AUTOSAR XML (schema 4-2-1)
standard types defined: boolean, uint8, uint16, uint32, uint64, sint8, sint16, sint32, sint64, float32, float64
package /ZARXML_DATA_TYPES
  impl type EDomainId: compu {0=EDomainId_VP, 1=EDomainId_Cluster, 2=EDomainId_IVI, 3=EDomainId_Last}, implementation-data-type=uint8
  impl type ESystemState: compu {0=ESystemState_Off, 1=ESystemState_Startup, 2=ESystemState_Up, 3=ESystemState_FullRun, 4=ESystemState_PrepareShutdown, 5=ESystemState_Minimal, 6=ESystemState_Meet, 7=ESystemState_Shutdown, 8=ESystemState_Last}, implementation-data-type=uint8
  impl type EDisplayPower: compu {0=EDisplayPower_Off, 1=EDisplayPower_On, 2=EDisplayPower_Last}, implementation-data-type=uint8
  4 x impl type:
    data_u8_15: category=ARRAY
      element Element: array-size=15, array-size-semantics=FIXED-SIZE, implementation-data-type=uint8
    data_u8_2: category=ARRAY
      element Element: array-size=2, array-size-semantics=FIXED-SIZE, implementation-data-type=uint8
    data_u8_8: category=ARRAY
      element Element: array-size=8, array-size-semantics=FIXED-SIZE, implementation-data-type=uint8
    EGaugeUnit: compu {0=EGaugeUnit_Mph, 1=EGaugeUnit_Kmph, 2=EGaugeUnit_Centigrade, 3=EGaugeUnit_Farenheit, 4=EGaugeUnit_Psi, 5=EGaugeUnit_Pa, 6=EGaugeUnit_Bar, 7=EGaugeUnit_Kmpl, 8=EGaugeUnit_Mpg, 9=EGaugeUnit_Ltr, 10=EGaugeUnit_Gal, 11=EGaugeUnit_Km, 12=EGaugeUnit_Mile, 13=EGaugeUnit_Last}, implementation-data-type=uint8
  8 x impl type:
    SGaugeInfo: category=STRUCTURE
      5 x element, all with category=TYPE_REFERENCE:
        id: implementation-data-type=uint8
        position: implementation-data-type=uint16
        digitalData: implementation-data-type=sint32
        unit: implementation-data-type=EGaugeUnit
        dynData: implementation-data-type=uint16
    SGaugeInfo_2: category=ARRAY
      element Element: array-size=2, array-size-semantics=FIXED-SIZE, implementation-data-type=SGaugeInfo
    SGaugeInfo_u32dyn: category=STRUCTURE
      5 x element, all with category=TYPE_REFERENCE:
        id: implementation-data-type=uint8
        position: implementation-data-type=uint16
        digitalData: implementation-data-type=uint32
        unit: implementation-data-type=EGaugeUnit
        dynData: implementation-data-type=uint32
    SGaugeInfo_u32dyn_3: category=ARRAY
      element Element: array-size=3, array-size-semantics=FIXED-SIZE, implementation-data-type=SGaugeInfo_u32dyn
    SShiftInd: category=STRUCTURE
      6 x element, all with category=TYPE_REFERENCE, implementation-data-type=uint8:
        Shift_Ind_Pos
        Shift_Ind_BlinkReq
        Shift_Ind_Up
        Shift_Ind_Down
        Shift_Ind_DisplayDecState
        Shift_Ind_Screen_ShiftType
    data_u8_64: category=ARRAY
      element Element: array-size=64, array-size-semantics=FIXED-SIZE, implementation-data-type=uint8
    data_u8_512: category=ARRAY
      element Element: array-size=512, array-size-semantics=FIXED-SIZE, implementation-data-type=uint8
    EDidType: compu {0=EDidType_Read, 1=EDidType_Write, 2=EDidType_Last}, implementation-data-type=uint8
  impl type data_u8_256: category=ARRAY
    element Element: array-size=256, array-size-semantics=FIXED-SIZE, implementation-data-type=uint8
  impl type EIOCtrlOptType: compu {0=EIOCtrlOptType_returnControlToECU, 1=EIOCtrlOptType_resetToDefault, 2=EIOCtrlOptType_freezeCurrentState, 3=EIOCtrlOptType_shortTermAdjustment, 4=EIOCtrlOptType_Last}, implementation-data-type=uint8
  impl type ERoutineType: compu {0=ERoutineType_Start, 1=ERoutineType_Stop, 2=ERoutineType_QueryResults, 3=ERoutineType_Last}, implementation-data-type=uint8
  impl type ECompState: compu {0=ECompState_Init, 1=ECompState_Start, 2=ECompState_Run, 3=ECompState_Stop, 4=ECompState_Shutdown, 5=ECompState_Last}, implementation-data-type=uint8
  impl type data_u8_32: category=ARRAY
    element Element: array-size=32, array-size-semantics=FIXED-SIZE, implementation-data-type=uint8
  impl type EDisplayStatus: compu {0=EDisplayState_Off, 1=EDisplayState_On, 2=EDisplayState_Error, 3=EDisplayState_Disconnected, 4=EDisplayState_Last}, implementation-data-type=uint8
  47 x impl type:
    data_u8_10: category=ARRAY
      element Element: array-size=10, array-size-semantics=FIXED-SIZE, implementation-data-type=uint8
    SPowerSystemStateReqChange: category=STRUCTURE
      element domainId: implementation-data-type=EDomainId
      element state: implementation-data-type=ESystemState
    SHealthDumpGetHdr: category=STRUCTURE
      element encrypt: implementation-data-type=uint8
    SHealthDumpGetData: category=STRUCTURE
      element reserved: implementation-data-type=uint8
    SDisplaySetPower: category=STRUCTURE
      element displayId: implementation-data-type=uint32
      element state: implementation-data-type=EDisplayPower
    STT_Status: category=STRUCTURE
      element mask: implementation-data-type=data_u8_15
    SRTT_Toggle: category=STRUCTURE
      element positions: implementation-data-type=uint8
      element display: implementation-data-type=uint8
    SFRTT_Status: category=STRUCTURE
      element mask: implementation-data-type=data_u8_2
    SRTT_Icon: category=STRUCTURE
      element icon: implementation-data-type=data_u8_2
    SRTT_Status: category=STRUCTURE
      element mask: implementation-data-type=data_u8_2
    SWarningExtDisplay: category=STRUCTURE
      element show: implementation-data-type=uint8
      element warningId: implementation-data-type=uint16
      element dynData: implementation-data-type=data_u8_8
    SWarningDisplay: category=STRUCTURE
      element show: implementation-data-type=uint8
      element warningId: implementation-data-type=uint16
      element dynData: implementation-data-type=data_u8_8
    SSlowGaugeInfo: category=STRUCTURE
      element gaugeInfo: implementation-data-type=SGaugeInfo_2
    SFastGaugeInfo: category=STRUCTURE
      element gaugeInfo: implementation-data-type=SGaugeInfo_u32dyn_3
    SShiftPosIndStatus: category=STRUCTURE
      element status: implementation-data-type=SShiftInd
    SIlluminationData: category=STRUCTURE
      4 x element, all with category=TYPE_REFERENCE, implementation-data-type=uint8:
        data
        dayStep
        nightStep
        daynightStatus
    SUpdateShortServiceReq: category=STRUCTURE
      7 x element, all with category=TYPE_REFERENCE:
        msgId: implementation-data-type=uint16
        msgSize: implementation-data-type=uint16
        memoryType: implementation-data-type=uint8
        memoryCmd: implementation-data-type=uint8
        sid: implementation-data-type=uint8
        length: implementation-data-type=uint32
        data: implementation-data-type=data_u8_64
    SUpdateLongServiceReq: category=STRUCTURE
      7 x element, all with category=TYPE_REFERENCE:
        msgId: implementation-data-type=uint16
        msgSize: implementation-data-type=uint16
        memoryType: implementation-data-type=uint8
        memoryCmd: implementation-data-type=uint8
        sid: implementation-data-type=uint8
        length: implementation-data-type=uint32
        data: implementation-data-type=data_u8_512
    SDiagDIDRequest: category=STRUCTURE
      4 x element, all with category=TYPE_REFERENCE:
        did: implementation-data-type=uint16
        didType: implementation-data-type=EDidType
        dataLen: implementation-data-type=uint16
        data: implementation-data-type=data_u8_256
    SDiagIOCtrlRequest: category=STRUCTURE
      4 x element, all with category=TYPE_REFERENCE:
        did: implementation-data-type=uint16
        optionCtrl: implementation-data-type=EIOCtrlOptType
        dataLen: implementation-data-type=uint16
        data: implementation-data-type=data_u8_256
    SDiagRoutineRequest: category=STRUCTURE
      4 x element, all with category=TYPE_REFERENCE:
        routineId: implementation-data-type=uint16
        routineType: implementation-data-type=ERoutineType
        dataLen: implementation-data-type=uint16
        data: implementation-data-type=data_u8_256
    SDLTMessageReadRequest: category=STRUCTURE
      element status: implementation-data-type=data_u8_2
    SDLTControlMessageReponse: category=STRUCTURE
      element status: implementation-data-type=data_u8_2
    SPowerSystemState: category=STRUCTURE
      element domainId: implementation-data-type=EDomainId
      element state: implementation-data-type=ESystemState
    SPowerExtendShutdownTime: category=STRUCTURE
      element domainId: implementation-data-type=EDomainId
      element timeoutMs: implementation-data-type=uint32
    SPowerKeepSystemAwake: category=STRUCTURE
      element domainId: implementation-data-type=EDomainId
      element timeoutMs: implementation-data-type=uint32
    SPowerSystemStateReqWakeLock: category=STRUCTURE
      element enable: implementation-data-type=uint8
      element requiredTimeMs: implementation-data-type=uint32
    SPowerReportCompState: category=STRUCTURE
      element state: implementation-data-type=ECompState
    SUclErrorNotify: category=STRUCTURE
      element errorCode: implementation-data-type=sint32
    SUclLinkStatus: category=STRUCTURE
      element status: implementation-data-type=sint32
    SHealthDomainHeartbeat: category=STRUCTURE
      element domainId: implementation-data-type=EDomainId
      element seqCnt: implementation-data-type=uint32
    SHealthDomainFatalError: category=STRUCTURE
      element domainId: implementation-data-type=EDomainId
      element compIdx: implementation-data-type=uint32
    SHealthEventRecord: category=STRUCTURE
      element recordType: implementation-data-type=uint8
      element recordLen: implementation-data-type=uint8
      element recordData: implementation-data-type=data_u8_8
    SHealthDumpHdrInfo: category=STRUCTURE
      element fileSize: implementation-data-type=uint32
    SHealthDumpData: category=STRUCTURE
      element chunkSize: implementation-data-type=uint32
      element data: implementation-data-type=data_u8_32
    SHealthGetStatus: category=STRUCTURE
      element compIdx: implementation-data-type=uint8
    SHealthStatusReport: category=STRUCTURE
      element timestamp: implementation-data-type=uint32
      element dataLen: implementation-data-type=uint16
      element data: implementation-data-type=data_u8_256
    SDisplayCurrentState: category=STRUCTURE
      element displayId: implementation-data-type=uint32
      element state: implementation-data-type=EDisplayStatus
    SEmmcErrorNotifier: category=STRUCTURE
      element errorCode: implementation-data-type=uint32
    SWarningDisplayAvailable: category=STRUCTURE
      element status: implementation-data-type=uint8
    SWarningStatus: category=STRUCTURE
      element visible: implementation-data-type=uint8
      element warningId: implementation-data-type=uint16
      element dynData: implementation-data-type=data_u8_10
    SSafeHMIReadyStatus: category=STRUCTURE
      element status: implementation-data-type=uint8
    SMainHMIReadyStatus: category=STRUCTURE
      element status: implementation-data-type=uint8
    SUpdateShortServiceResp: category=STRUCTURE
      7 x element, all with category=TYPE_REFERENCE:
        msgId: implementation-data-type=uint16
        msgSize: implementation-data-type=uint16
        sid: implementation-data-type=uint8
        length: implementation-data-type=uint16
        responseCode: implementation-data-type=uint8
        NRC: implementation-data-type=uint8
        data: implementation-data-type=data_u8_64
    SDiagResponse: category=STRUCTURE
      element responseCode: implementation-data-type=uint8
      element dataLen: implementation-data-type=uint16
      element data: implementation-data-type=data_u8_256
    SDLTMessageReadAck: category=STRUCTURE
      element status: implementation-data-type=data_u8_2
    SDLTControlMessageRequest: category=STRUCTURE
      element status: implementation-data-type=data_u8_2
package /ZARXML_PORT_IF
  46 x sender receiver interface:
    PowerSystemStateReqChange: invalidation-policy=PowerSystemStateReqChangeData
      data PowerSystemStateReqChangeData: type=SPowerSystemStateReqChange
    HealthDumpGetHdr_Q: invalidation-policy=HealthDumpGetHdrData
      data HealthDumpGetHdrData: sw-impl-policy=QUEUED, type=SHealthDumpGetHdr
    HealthDumpGetData_Q: invalidation-policy=HealthDumpGetDataData
      data HealthDumpGetDataData: sw-impl-policy=QUEUED, type=SHealthDumpGetData
    DisplaySetPower: invalidation-policy=DisplaySetPowerData
      data DisplaySetPowerData: type=SDisplaySetPower
    TT_Status: invalidation-policy=TT_StatusData
      data TT_StatusData: type=STT_Status
    RTT_Toggle: invalidation-policy=RTT_ToggleData
      data RTT_ToggleData: type=SRTT_Toggle
    FRTT_Status: invalidation-policy=FRTT_StatusData
      data FRTT_StatusData: type=SFRTT_Status
    RTT_Icon: invalidation-policy=RTT_IconData
      data RTT_IconData: type=SRTT_Icon
    RTT_Status: invalidation-policy=RTT_StatusData
      data RTT_StatusData: type=SRTT_Status
    WarningExtDisplay: invalidation-policy=WarningExtDisplayData
      data WarningExtDisplayData: type=SWarningExtDisplay
    WarningDisplay: invalidation-policy=WarningDisplayData
      data WarningDisplayData: type=SWarningDisplay
    SlowGaugeInfo: invalidation-policy=SlowGaugeInfoData
      data SlowGaugeInfoData: type=SSlowGaugeInfo
    FastGaugeInfo: invalidation-policy=FastGaugeInfoData
      data FastGaugeInfoData: type=SFastGaugeInfo
    ShiftPosIndStatus: invalidation-policy=ShiftPosIndStatusData
      data ShiftPosIndStatusData: type=SShiftPosIndStatus
    IlluminationData: invalidation-policy=IlluminationDataData
      data IlluminationDataData: type=SIlluminationData
    UpdateShortServiceReq_Q: invalidation-policy=UpdateShortServiceReqData
      data UpdateShortServiceReqData: sw-impl-policy=QUEUED, type=SUpdateShortServiceReq
    UpdateLongServiceReq_Q: invalidation-policy=UpdateLongServiceReqData
      data UpdateLongServiceReqData: sw-impl-policy=QUEUED, type=SUpdateLongServiceReq
    DiagDIDRequest_Q: invalidation-policy=DiagDIDRequestData
      data DiagDIDRequestData: sw-impl-policy=QUEUED, type=SDiagDIDRequest
    DiagIOCtrlRequest_Q: invalidation-policy=DiagIOCtrlRequestData
      data DiagIOCtrlRequestData: sw-impl-policy=QUEUED, type=SDiagIOCtrlRequest
    DiagRoutineRequest_Q: invalidation-policy=DiagRoutineRequestData
      data DiagRoutineRequestData: sw-impl-policy=QUEUED, type=SDiagRoutineRequest
    DLTMessageReadRequest: invalidation-policy=DLTMessageReadRequestData
      data DLTMessageReadRequestData: type=SDLTMessageReadRequest
    DLTControlMessageReponse: invalidation-policy=DLTControlMessageReponseData
      data DLTControlMessageReponseData: type=SDLTControlMessageReponse
    PowerSystemState: invalidation-policy=PowerSystemStateData
      data PowerSystemStateData: type=SPowerSystemState
    PowerExtendShutdownTime_Q: invalidation-policy=PowerExtendShutdownTimeData
      data PowerExtendShutdownTimeData: sw-impl-policy=QUEUED, type=SPowerExtendShutdownTime
    PowerKeepSystemAwake_Q: invalidation-policy=PowerKeepSystemAwakeData
      data PowerKeepSystemAwakeData: sw-impl-policy=QUEUED, type=SPowerKeepSystemAwake
    PowerSystemStateReqWakeLock_Q: invalidation-policy=PowerSystemStateReqWakeLockData
      data PowerSystemStateReqWakeLockData: sw-impl-policy=QUEUED, type=SPowerSystemStateReqWakeLock
    PowerReportCompState_Q: invalidation-policy=PowerReportCompStateData
      data PowerReportCompStateData: sw-impl-policy=QUEUED, type=SPowerReportCompState
    UclErrorNotify_Q: invalidation-policy=UclErrorNotifyData
      data UclErrorNotifyData: sw-impl-policy=QUEUED, type=SUclErrorNotify
    UclLinkStatus_Q: invalidation-policy=UclLinkStatusData
      data UclLinkStatusData: sw-impl-policy=QUEUED, type=SUclLinkStatus
    HealthDomainHeartbeat_Q: invalidation-policy=HealthDomainHeartbeatData
      data HealthDomainHeartbeatData: sw-impl-policy=QUEUED, type=SHealthDomainHeartbeat
    HealthDomainFatalError_Q: invalidation-policy=HealthDomainFatalErrorData
      data HealthDomainFatalErrorData: sw-impl-policy=QUEUED, type=SHealthDomainFatalError
    HealthEventRecord_Q: invalidation-policy=HealthEventRecordData
      data HealthEventRecordData: sw-impl-policy=QUEUED, type=SHealthEventRecord
    HealthDumpHdrInfo_Q: invalidation-policy=HealthDumpHdrInfoData
      data HealthDumpHdrInfoData: sw-impl-policy=QUEUED, type=SHealthDumpHdrInfo
    HealthDumpData_Q: invalidation-policy=HealthDumpDataData
      data HealthDumpDataData: sw-impl-policy=QUEUED, type=SHealthDumpData
    HealthGetStatus_Q: invalidation-policy=HealthGetStatusData
      data HealthGetStatusData: sw-impl-policy=QUEUED, type=SHealthGetStatus
    HealthStatusReport_Q: invalidation-policy=HealthStatusReportData
      data HealthStatusReportData: sw-impl-policy=QUEUED, type=SHealthStatusReport
    DisplayCurrentState: invalidation-policy=DisplayCurrentStateData
      data DisplayCurrentStateData: type=SDisplayCurrentState
    EmmcErrorNotifier: invalidation-policy=EmmcErrorNotifierData
      data EmmcErrorNotifierData: type=SEmmcErrorNotifier
    WarningDisplayAvailable: invalidation-policy=WarningDisplayAvailableData
      data WarningDisplayAvailableData: type=SWarningDisplayAvailable
    WarningStatus: invalidation-policy=WarningStatusData
      data WarningStatusData: type=SWarningStatus
    SafeHMIReadyStatus_Q: invalidation-policy=SafeHMIReadyStatusData
      data SafeHMIReadyStatusData: sw-impl-policy=QUEUED, type=SSafeHMIReadyStatus
    MainHMIReadyStatus_Q: invalidation-policy=MainHMIReadyStatusData
      data MainHMIReadyStatusData: sw-impl-policy=QUEUED, type=SMainHMIReadyStatus
    UpdateShortServiceResp_Q: invalidation-policy=UpdateShortServiceRespData
      data UpdateShortServiceRespData: sw-impl-policy=QUEUED, type=SUpdateShortServiceResp
    DiagResponse_Q: invalidation-policy=DiagResponseData
      data DiagResponseData: sw-impl-policy=QUEUED, type=SDiagResponse
    DLTMessageReadAck: invalidation-policy=DLTMessageReadAckData
      data DLTMessageReadAckData: type=SDLTMessageReadAck
    DLTControlMessageRequest: invalidation-policy=DLTControlMessageRequestData
      data DLTControlMessageRequestData: type=SDLTControlMessageRequest
  client server interface UclInitShutdown
    operation Initialize: possible-error=UclInitShutdown/E_OK
    operation Shutdown: possible-error=UclInitShutdown/E_OK
    error E_OK: error-code=0
  client server interface UclCmplibCmd
    operation OnCommand: possible-error=UclCmplibCmd/E_OK
      arg Cmd: type=uint8, direction=IN
    error E_OK: error-code=0
  client server interface UclSystemCallbacks
    operation ErrorNotification
      arg DLInst: type=uint8, direction=IN
      arg ErrorCode: type=sint32, direction=IN
    operation LinkStatusChanged
      arg DLInst: type=uint8, direction=IN
      arg Status: type=sint32, direction=IN
  sender receiver interface UclTxStatuses
package /ZARXML_CMP
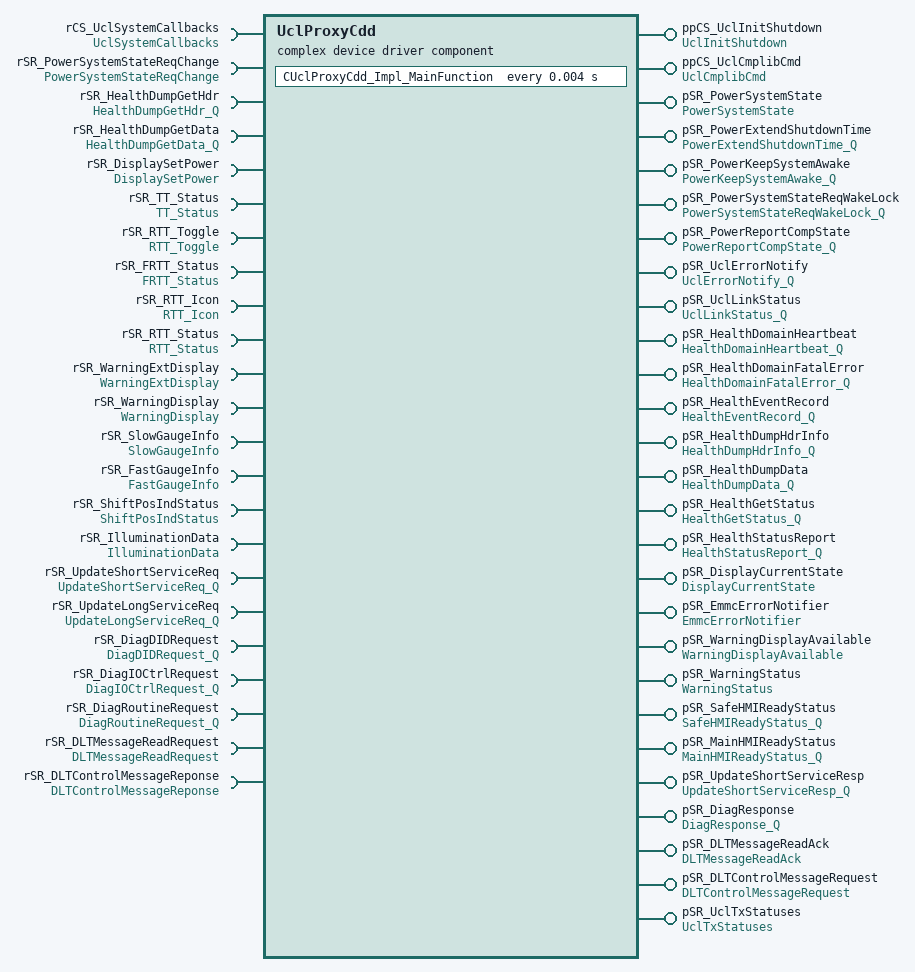
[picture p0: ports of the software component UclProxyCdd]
  complex device driver sw component type UclProxyCdd
    provide port ppCS_UclInitShutdown: provided-interface=UclInitShutdown
    provide port ppCS_UclCmplibCmd: provided-interface=UclCmplibCmd
    require port rCS_UclSystemCallbacks: required-interface=UclSystemCallbacks
    24 x provide port:
      pSR_PowerSystemState: nonqueued-sender-com-spec{data-element=PowerSystemStateData, init-value={short-label=SPowerSystemState, fields=[EDomainId:0, ESystemState:0]}}, provided-interface=PowerSystemState
      pSR_PowerExtendShutdownTime: queued-sender-com-spec=data-element=PowerExtendShutdownTimeData, provided-interface=PowerExtendShutdownTime_Q
      pSR_PowerKeepSystemAwake: queued-sender-com-spec=data-element=PowerKeepSystemAwakeData, provided-interface=PowerKeepSystemAwake_Q
      pSR_PowerSystemStateReqWakeLock: queued-sender-com-spec=data-element=PowerSystemStateReqWakeLockData, provided-interface=PowerSystemStateReqWakeLock_Q
      pSR_PowerReportCompState: queued-sender-com-spec=data-element=PowerReportCompStateData, provided-interface=PowerReportCompState_Q
      pSR_UclErrorNotify: queued-sender-com-spec=data-element=UclErrorNotifyData, provided-interface=UclErrorNotify_Q
      pSR_UclLinkStatus: queued-sender-com-spec=data-element=UclLinkStatusData, provided-interface=UclLinkStatus_Q
      pSR_HealthDomainHeartbeat: queued-sender-com-spec=data-element=HealthDomainHeartbeatData, provided-interface=HealthDomainHeartbeat_Q
      pSR_HealthDomainFatalError: queued-sender-com-spec=data-element=HealthDomainFatalErrorData, provided-interface=HealthDomainFatalError_Q
      pSR_HealthEventRecord: queued-sender-com-spec=data-element=HealthEventRecordData, provided-interface=HealthEventRecord_Q
      pSR_HealthDumpHdrInfo: queued-sender-com-spec=data-element=HealthDumpHdrInfoData, provided-interface=HealthDumpHdrInfo_Q
      pSR_HealthDumpData: queued-sender-com-spec=data-element=HealthDumpDataData, provided-interface=HealthDumpData_Q
      pSR_HealthGetStatus: queued-sender-com-spec=data-element=HealthGetStatusData, provided-interface=HealthGetStatus_Q
      pSR_HealthStatusReport: queued-sender-com-spec=data-element=HealthStatusReportData, provided-interface=HealthStatusReport_Q
      pSR_DisplayCurrentState: nonqueued-sender-com-spec{data-element=DisplayCurrentStateData, init-value={short-label=SDisplayCurrentState, fields=[uint32:0, EDisplayStatus:0]}}, provided-interface=DisplayCurrentState
      pSR_EmmcErrorNotifier: nonqueued-sender-com-spec{data-element=EmmcErrorNotifierData, init-value={short-label=SEmmcErrorNotifier, fields=uint32:0}}, provided-interface=EmmcErrorNotifier
      pSR_WarningDisplayAvailable: nonqueued-sender-com-spec{data-element=WarningDisplayAvailableData, init-value={short-label=SWarningDisplayAvailable, fields=uint8:0}}, provided-interface=WarningDisplayAvailable
      pSR_WarningStatus: nonqueued-sender-com-spec{data-element=WarningStatusData, init-value={short-label=SWarningStatus, fields=[uint8:0, uint16:0, data_u8_10:10 x uint8:0]}}, provided-interface=WarningStatus
      pSR_SafeHMIReadyStatus: queued-sender-com-spec=data-element=SafeHMIReadyStatusData, provided-interface=SafeHMIReadyStatus_Q
      pSR_MainHMIReadyStatus: queued-sender-com-spec=data-element=MainHMIReadyStatusData, provided-interface=MainHMIReadyStatus_Q
      pSR_UpdateShortServiceResp: queued-sender-com-spec=data-element=UpdateShortServiceRespData, provided-interface=UpdateShortServiceResp_Q
      pSR_DiagResponse: queued-sender-com-spec=data-element=DiagResponseData, provided-interface=DiagResponse_Q
      pSR_DLTMessageReadAck: nonqueued-sender-com-spec{data-element=DLTMessageReadAckData, init-value={short-label=SDLTMessageReadAck, fields=data_u8_2:[uint8:0, uint8:0]}}, provided-interface=DLTMessageReadAck
      pSR_DLTControlMessageRequest: nonqueued-sender-com-spec{data-element=DLTControlMessageRequestData, init-value={short-label=SDLTControlMessageRequest, fields=data_u8_2:[uint8:0, uint8:0]}}, provided-interface=DLTControlMessageRequest
    22 x require port:
      rSR_PowerSystemStateReqChange: nonqueued-receiver-com-spec{data-element=PowerSystemStateReqChangeData, init-value={short-label=SPowerSystemStateReqChange, fields=[EDomainId:0, ESystemState:ESystemState_Last]}}, required-interface=PowerSystemStateReqChange
      rSR_HealthDumpGetHdr: queued-receiver-com-spec{data-element=HealthDumpGetHdrData, queue-length=1}, required-interface=HealthDumpGetHdr_Q
      rSR_HealthDumpGetData: queued-receiver-com-spec{data-element=HealthDumpGetDataData, queue-length=1}, required-interface=HealthDumpGetData_Q
      rSR_DisplaySetPower: nonqueued-receiver-com-spec{data-element=DisplaySetPowerData, init-value={short-label=SDisplaySetPower, fields=[uint32:0, EDisplayPower:0]}}, required-interface=DisplaySetPower
      rSR_TT_Status: nonqueued-receiver-com-spec{data-element=TT_StatusData, init-value={short-label=STT_Status, fields=data_u8_15:15 x uint8:0}}, required-interface=TT_Status
      rSR_RTT_Toggle: nonqueued-receiver-com-spec{data-element=RTT_ToggleData, init-value={short-label=SRTT_Toggle, fields=[uint8:0, uint8:0]}}, required-interface=RTT_Toggle
      rSR_FRTT_Status: nonqueued-receiver-com-spec{data-element=FRTT_StatusData, init-value={short-label=SFRTT_Status, fields=data_u8_2:[uint8:0, uint8:0]}}, required-interface=FRTT_Status
      rSR_RTT_Icon: nonqueued-receiver-com-spec{data-element=RTT_IconData, init-value={short-label=SRTT_Icon, fields=data_u8_2:[uint8:0, uint8:0]}}, required-interface=RTT_Icon
      rSR_RTT_Status: nonqueued-receiver-com-spec{data-element=RTT_StatusData, init-value={short-label=SRTT_Status, fields=data_u8_2:[uint8:0, uint8:0]}}, required-interface=RTT_Status
      rSR_WarningExtDisplay: nonqueued-receiver-com-spec{data-element=WarningExtDisplayData, init-value={short-label=SWarningExtDisplay, fields=[uint8:0, uint16:0, data_u8_8:8 x uint8:0]}}, required-interface=WarningExtDisplay
      rSR_WarningDisplay: nonqueued-receiver-com-spec{data-element=WarningDisplayData, init-value={short-label=SWarningDisplay, fields=[uint8:0, uint16:0, data_u8_8:8 x uint8:0]}}, required-interface=WarningDisplay
      rSR_SlowGaugeInfo: nonqueued-receiver-com-spec{data-element=SlowGaugeInfoData, init-value={short-label=SSlowGaugeInfo, fields=SGaugeInfo_2:[{short-label=SGaugeInfo, fields=[uint8:0, uint16:0, sint32:0, EGaugeUnit:EGaugeUnit_Last, uint16:0]}, {short-label=SGaugeInfo, fields=[uint8:0, uint16:0, sint32:0, EGaugeUnit:EGaugeUnit_Last, uint16:0]}]}}, required-interface=SlowGaugeInfo
      rSR_FastGaugeInfo: nonqueued-receiver-com-spec{data-element=FastGaugeInfoData, init-value={short-label=SFastGaugeInfo, fields=SGaugeInfo_u32dyn_3:[{short-label=SGaugeInfo_u32dyn, fields=[uint8:0, uint16:0, uint32:0, EGaugeUnit:EGaugeUnit_Last, uint32:0]}, {short-label=SGaugeInfo_u32dyn, fields=[uint8:0, uint16:0, uint32:0, EGaugeUnit:EGaugeUnit_Last, uint32:0]}, {short-label=SGaugeInfo_u32dyn, fields=[uint8:0, uint16:0, uint32:0, EGaugeUnit:EGaugeUnit_Last, uint32:0]}]}}, required-interface=FastGaugeInfo
      rSR_ShiftPosIndStatus: nonqueued-receiver-com-spec{data-element=ShiftPosIndStatusData, init-value={short-label=SShiftPosIndStatus, fields={short-label=SShiftInd, fields=[uint8:0, uint8:0, uint8:0, uint8:0, uint8:0, uint8:0]}}}, required-interface=ShiftPosIndStatus
      rSR_IlluminationData: nonqueued-receiver-com-spec{data-element=IlluminationDataData, init-value={short-label=SIlluminationData, fields=[uint8:0, uint8:0, uint8:0, uint8:0]}}, required-interface=IlluminationData
      rSR_UpdateShortServiceReq: queued-receiver-com-spec{data-element=UpdateShortServiceReqData, queue-length=2}, required-interface=UpdateShortServiceReq_Q
      rSR_UpdateLongServiceReq: queued-receiver-com-spec{data-element=UpdateLongServiceReqData, queue-length=2}, required-interface=UpdateLongServiceReq_Q
      rSR_DiagDIDRequest: queued-receiver-com-spec{data-element=DiagDIDRequestData, queue-length=2}, required-interface=DiagDIDRequest_Q
      rSR_DiagIOCtrlRequest: queued-receiver-com-spec{data-element=DiagIOCtrlRequestData, queue-length=2}, required-interface=DiagIOCtrlRequest_Q
      rSR_DiagRoutineRequest: queued-receiver-com-spec{data-element=DiagRoutineRequestData, queue-length=2}, required-interface=DiagRoutineRequest_Q
      rSR_DLTMessageReadRequest: nonqueued-receiver-com-spec{data-element=DLTMessageReadRequestData, init-value={short-label=SDLTMessageReadRequest, fields=data_u8_2:[uint8:0, uint8:0]}}, required-interface=DLTMessageReadRequest
      rSR_DLTControlMessageReponse: nonqueued-receiver-com-spec{data-element=DLTControlMessageReponseData, init-value={short-label=SDLTControlMessageReponse, fields=data_u8_2:[uint8:0, uint8:0]}}, required-interface=DLTControlMessageReponse
    provide port pSR_UclTxStatuses: provided-interface=UclTxStatuses
    behavior UclProxyCdd_IB: handle-termination-and-restart=NO-SUPPORT
      operation invoked event OI_ppCS_UclInitShutdown_Initialize: start-on-event=CUclProxyCdd_Impl_Initialize, operation=ppCS_UclInitShutdown.Initialize
      operation invoked event OI_ppCS_UclInitShutdown_Shutdown: start-on-event=CUclProxyCdd_Impl_Shutdown, operation=ppCS_UclInitShutdown.Shutdown
      operation invoked event OI_ppCS_UclCmplibCmd_OnCommand: start-on-event=CUclProxyCdd_Impl_OnCommand, operation=ppCS_UclCmplibCmd.OnCommand
      22 x data received event:
        DRE_rSR_PowerSystemStateReqChange_PowerSystemStateReqChangeData_OnDre_PowerSystemStateReqChange: start-on-event=OnDre_PowerSystemStateReqChange, data=rSR_PowerSystemStateReqChange.PowerSystemStateReqChangeData
        DRE_rSR_HealthDumpGetHdr_HealthDumpGetHdrData_OnDre_HealthDumpGetHdr: start-on-event=OnDre_HealthDumpGetHdr, data=rSR_HealthDumpGetHdr.HealthDumpGetHdrData
        DRE_rSR_HealthDumpGetData_HealthDumpGetDataData_OnDre_HealthDumpGetData: start-on-event=OnDre_HealthDumpGetData, data=rSR_HealthDumpGetData.HealthDumpGetDataData
        DRE_rSR_DisplaySetPower_DisplaySetPowerData_OnDre_DisplaySetPower: start-on-event=OnDre_DisplaySetPower, data=rSR_DisplaySetPower.DisplaySetPowerData
        DRE_rSR_TT_Status_TT_StatusData_OnDre_TT_Status: start-on-event=OnDre_TT_Status, data=rSR_TT_Status.TT_StatusData
        DRE_rSR_RTT_Toggle_RTT_ToggleData_OnDre_RTT_Toggle: start-on-event=OnDre_RTT_Toggle, data=rSR_RTT_Toggle.RTT_ToggleData
        DRE_rSR_FRTT_Status_FRTT_StatusData_OnDre_FRTT_Status: start-on-event=OnDre_FRTT_Status, data=rSR_FRTT_Status.FRTT_StatusData
        DRE_rSR_RTT_Icon_RTT_IconData_OnDre_RTT_Icon: start-on-event=OnDre_RTT_Icon, data=rSR_RTT_Icon.RTT_IconData
        DRE_rSR_RTT_Status_RTT_StatusData_OnDre_RTT_Status: start-on-event=OnDre_RTT_Status, data=rSR_RTT_Status.RTT_StatusData
        DRE_rSR_WarningExtDisplay_WarningExtDisplayData_OnDre_WarningExtDisplay: start-on-event=OnDre_WarningExtDisplay, data=rSR_WarningExtDisplay.WarningExtDisplayData
        DRE_rSR_WarningDisplay_WarningDisplayData_OnDre_WarningDisplay: start-on-event=OnDre_WarningDisplay, data=rSR_WarningDisplay.WarningDisplayData
        DRE_rSR_SlowGaugeInfo_SlowGaugeInfoData_OnDre_SlowGaugeInfo: start-on-event=OnDre_SlowGaugeInfo, data=rSR_SlowGaugeInfo.SlowGaugeInfoData
        DRE_rSR_FastGaugeInfo_FastGaugeInfoData_OnDre_FastGaugeInfo: start-on-event=OnDre_FastGaugeInfo, data=rSR_FastGaugeInfo.FastGaugeInfoData
        DRE_rSR_ShiftPosIndStatus_ShiftPosIndStatusData_OnDre_ShiftPosIndStatus: start-on-event=OnDre_ShiftPosIndStatus, data=rSR_ShiftPosIndStatus.ShiftPosIndStatusData
        DRE_rSR_IlluminationData_IlluminationDataData_OnDre_IlluminationData: start-on-event=OnDre_IlluminationData, data=rSR_IlluminationData.IlluminationDataData
        DRE_rSR_UpdateShortServiceReq_UpdateShortServiceReqData_OnDre_UpdateShortServiceReq: start-on-event=OnDre_UpdateShortServiceReq, data=rSR_UpdateShortServiceReq.UpdateShortServiceReqData
        DRE_rSR_UpdateLongServiceReq_UpdateLongServiceReqData_OnDre_UpdateLongServiceReq: start-on-event=OnDre_UpdateLongServiceReq, data=rSR_UpdateLongServiceReq.UpdateLongServiceReqData
        DRE_rSR_DiagDIDRequest_DiagDIDRequestData_OnDre_DiagDIDRequest: start-on-event=OnDre_DiagDIDRequest, data=rSR_DiagDIDRequest.DiagDIDRequestData
        DRE_rSR_DiagIOCtrlRequest_DiagIOCtrlRequestData_OnDre_DiagIOCtrlRequest: start-on-event=OnDre_DiagIOCtrlRequest, data=rSR_DiagIOCtrlRequest.DiagIOCtrlRequestData
        DRE_rSR_DiagRoutineRequest_DiagRoutineRequestData_OnDre_DiagRoutineRequest: start-on-event=OnDre_DiagRoutineRequest, data=rSR_DiagRoutineRequest.DiagRoutineRequestData
        DRE_rSR_DLTMessageReadRequest_DLTMessageReadRequestData_OnDre_DLTMessageReadRequest: start-on-event=OnDre_DLTMessageReadRequest, data=rSR_DLTMessageReadRequest.DLTMessageReadRequestData
        DRE_rSR_DLTControlMessageReponse_DLTControlMessageReponseData_OnDre_DLTControlMessageReponse: start-on-event=OnDre_DLTControlMessageReponse, data=rSR_DLTControlMessageReponse.DLTControlMessageReponseData
      timing event TE_CUclProxyCdd_Impl_MainFunction: start-on-event=CUclProxyCdd_Impl_MainFunction, period=0.004
      26 x runnable:
        CUclProxyCdd_Impl_MainFunction
          data-receive-point-by-arguments:
            22 x access:
              READ_rSR_PowerSystemStateReqChange_PowerSystemStateReqChangeData: accessed-variable=rSR_PowerSystemStateReqChange.PowerSystemStateReqChangeData
              READ_rSR_HealthDumpGetHdr_HealthDumpGetHdrData: accessed-variable=rSR_HealthDumpGetHdr.HealthDumpGetHdrData
              READ_rSR_HealthDumpGetData_HealthDumpGetDataData: accessed-variable=rSR_HealthDumpGetData.HealthDumpGetDataData
              READ_rSR_DisplaySetPower_DisplaySetPowerData: accessed-variable=rSR_DisplaySetPower.DisplaySetPowerData
              READ_rSR_TT_Status_TT_StatusData: accessed-variable=rSR_TT_Status.TT_StatusData
              READ_rSR_RTT_Toggle_RTT_ToggleData: accessed-variable=rSR_RTT_Toggle.RTT_ToggleData
              READ_rSR_FRTT_Status_FRTT_StatusData: accessed-variable=rSR_FRTT_Status.FRTT_StatusData
              READ_rSR_RTT_Icon_RTT_IconData: accessed-variable=rSR_RTT_Icon.RTT_IconData
              READ_rSR_RTT_Status_RTT_StatusData: accessed-variable=rSR_RTT_Status.RTT_StatusData
              READ_rSR_WarningExtDisplay_WarningExtDisplayData: accessed-variable=rSR_WarningExtDisplay.WarningExtDisplayData
              READ_rSR_WarningDisplay_WarningDisplayData: accessed-variable=rSR_WarningDisplay.WarningDisplayData
              READ_rSR_SlowGaugeInfo_SlowGaugeInfoData: accessed-variable=rSR_SlowGaugeInfo.SlowGaugeInfoData
              READ_rSR_FastGaugeInfo_FastGaugeInfoData: accessed-variable=rSR_FastGaugeInfo.FastGaugeInfoData
              READ_rSR_ShiftPosIndStatus_ShiftPosIndStatusData: accessed-variable=rSR_ShiftPosIndStatus.ShiftPosIndStatusData
              READ_rSR_IlluminationData_IlluminationDataData: accessed-variable=rSR_IlluminationData.IlluminationDataData
              READ_rSR_UpdateShortServiceReq_UpdateShortServiceReqData: accessed-variable=rSR_UpdateShortServiceReq.UpdateShortServiceReqData
              READ_rSR_UpdateLongServiceReq_UpdateLongServiceReqData: accessed-variable=rSR_UpdateLongServiceReq.UpdateLongServiceReqData
              READ_rSR_DiagDIDRequest_DiagDIDRequestData: accessed-variable=rSR_DiagDIDRequest.DiagDIDRequestData
              READ_rSR_DiagIOCtrlRequest_DiagIOCtrlRequestData: accessed-variable=rSR_DiagIOCtrlRequest.DiagIOCtrlRequestData
              READ_rSR_DiagRoutineRequest_DiagRoutineRequestData: accessed-variable=rSR_DiagRoutineRequest.DiagRoutineRequestData
              READ_rSR_DLTMessageReadRequest_DLTMessageReadRequestData: accessed-variable=rSR_DLTMessageReadRequest.DLTMessageReadRequestData
              READ_rSR_DLTControlMessageReponse_DLTControlMessageReponseData: accessed-variable=rSR_DLTControlMessageReponse.DLTControlMessageReponseData
          data-send-points:
            24 x access:
              WRITE_pSR_PowerSystemState_PowerSystemStateData: accessed-variable=pSR_PowerSystemState.PowerSystemStateData
              WRITE_pSR_PowerExtendShutdownTime_PowerExtendShutdownTimeData: accessed-variable=pSR_PowerExtendShutdownTime.PowerExtendShutdownTimeData
              WRITE_pSR_PowerKeepSystemAwake_PowerKeepSystemAwakeData: accessed-variable=pSR_PowerKeepSystemAwake.PowerKeepSystemAwakeData
              WRITE_pSR_PowerSystemStateReqWakeLock_PowerSystemStateReqWakeLockData: accessed-variable=pSR_PowerSystemStateReqWakeLock.PowerSystemStateReqWakeLockData
              WRITE_pSR_PowerReportCompState_PowerReportCompStateData: accessed-variable=pSR_PowerReportCompState.PowerReportCompStateData
              WRITE_pSR_UclErrorNotify_UclErrorNotifyData: accessed-variable=pSR_UclErrorNotify.UclErrorNotifyData
              WRITE_pSR_UclLinkStatus_UclLinkStatusData: accessed-variable=pSR_UclLinkStatus.UclLinkStatusData
              WRITE_pSR_HealthDomainHeartbeat_HealthDomainHeartbeatData: accessed-variable=pSR_HealthDomainHeartbeat.HealthDomainHeartbeatData
              WRITE_pSR_HealthDomainFatalError_HealthDomainFatalErrorData: accessed-variable=pSR_HealthDomainFatalError.HealthDomainFatalErrorData
              WRITE_pSR_HealthEventRecord_HealthEventRecordData: accessed-variable=pSR_HealthEventRecord.HealthEventRecordData
              WRITE_pSR_HealthDumpHdrInfo_HealthDumpHdrInfoData: accessed-variable=pSR_HealthDumpHdrInfo.HealthDumpHdrInfoData
              WRITE_pSR_HealthDumpData_HealthDumpDataData: accessed-variable=pSR_HealthDumpData.HealthDumpDataData
              WRITE_pSR_HealthGetStatus_HealthGetStatusData: accessed-variable=pSR_HealthGetStatus.HealthGetStatusData
              WRITE_pSR_HealthStatusReport_HealthStatusReportData: accessed-variable=pSR_HealthStatusReport.HealthStatusReportData
              WRITE_pSR_DisplayCurrentState_DisplayCurrentStateData: accessed-variable=pSR_DisplayCurrentState.DisplayCurrentStateData
              WRITE_pSR_EmmcErrorNotifier_EmmcErrorNotifierData: accessed-variable=pSR_EmmcErrorNotifier.EmmcErrorNotifierData
              WRITE_pSR_WarningDisplayAvailable_WarningDisplayAvailableData: accessed-variable=pSR_WarningDisplayAvailable.WarningDisplayAvailableData
              WRITE_pSR_WarningStatus_WarningStatusData: accessed-variable=pSR_WarningStatus.WarningStatusData
              WRITE_pSR_SafeHMIReadyStatus_SafeHMIReadyStatusData: accessed-variable=pSR_SafeHMIReadyStatus.SafeHMIReadyStatusData
              WRITE_pSR_MainHMIReadyStatus_MainHMIReadyStatusData: accessed-variable=pSR_MainHMIReadyStatus.MainHMIReadyStatusData
              WRITE_pSR_UpdateShortServiceResp_UpdateShortServiceRespData: accessed-variable=pSR_UpdateShortServiceResp.UpdateShortServiceRespData
              WRITE_pSR_DiagResponse_DiagResponseData: accessed-variable=pSR_DiagResponse.DiagResponseData
              WRITE_pSR_DLTMessageReadAck_DLTMessageReadAckData: accessed-variable=pSR_DLTMessageReadAck.DLTMessageReadAckData
              WRITE_pSR_DLTControlMessageRequest_DLTControlMessageRequestData: accessed-variable=pSR_DLTControlMessageRequest.DLTControlMessageRequestData
          sync call CALL_rCS_UclSystemCallbacks_ErrorNotification: operation=rCS_UclSystemCallbacks.ErrorNotification, timeout=0.0
          sync call CALL_rCS_UclSystemCallbacks_LinkStatusChanged: operation=rCS_UclSystemCallbacks.LinkStatusChanged, timeout=0.0
        CUclProxyCdd_Impl_Initialize
        CUclProxyCdd_Impl_Shutdown
        CUclProxyCdd_Impl_OnCommand
        OnDre_PowerSystemStateReqChange
        OnDre_HealthDumpGetHdr
        OnDre_HealthDumpGetData
        OnDre_DisplaySetPower
        OnDre_TT_Status
        OnDre_RTT_Toggle
        OnDre_FRTT_Status
        OnDre_RTT_Icon
        OnDre_RTT_Status
        OnDre_WarningExtDisplay
        OnDre_WarningDisplay
        OnDre_SlowGaugeInfo
        OnDre_FastGaugeInfo
        OnDre_ShiftPosIndStatus
        OnDre_IlluminationData
        OnDre_UpdateShortServiceReq
        OnDre_UpdateLongServiceReq
        OnDre_DiagDIDRequest
        OnDre_DiagIOCtrlRequest
        OnDre_DiagRoutineRequest
        OnDre_DLTMessageReadRequest
        OnDre_DLTControlMessageReponse
  swc implementation UclProxyCdd_Implementation: behavior=UclProxyCdd_IB
    code-descriptors:
      code Default: artifact-descriptors=autosar-engineering-object={short-label=Default, category=SWSRC}
